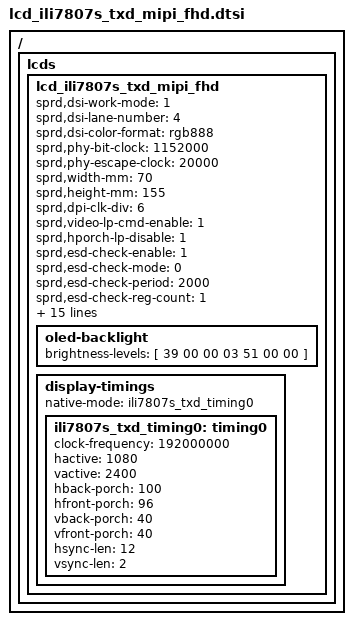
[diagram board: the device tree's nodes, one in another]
/*
 *  ili7807s LCD config dtsi file for spreadtrum
 *
 * Copyright (C) 2022, Spreadtrum Communications Inc.
 *
 * SPDX-License-Identifier: (GPL-2.0+ OR MIT)
 */
 
/ {
	fragment {
		target-path = "/";
		__overlay__ {
			lcds {
				lcd_ili7807s_txd_mipi_fhd: lcd_ili7807s_txd_mipi_fhd {

					sprd,dsi-work-mode = <1>;          /* video burst mode*/
					sprd,dsi-lane-number = <4>;
					sprd,dsi-color-format = "rgb888";

					sprd,phy-bit-clock = <1152000>;    /* kbps */
					sprd,phy-escape-clock = <20000>;   /* kHz */
					/* sprd,power-gpio-delay = <20>;      ms */
					sprd,width-mm = <70>;
					sprd,height-mm = <155>;
					sprd,dpi-clk-div = <6>;
					sprd,video-lp-cmd-enable = <1>;
					sprd,hporch-lp-disable = <1>;

					sprd,esd-check-enable = <1>;
					sprd,esd-check-mode = <0>;
					sprd,esd-check-period = <2000>;
					sprd,esd-check-reg-count = <1>;
					sprd,esd-check-register = [0A];
					sprd,esd-check-value-len = <1>;
					sprd,esd-check-value = [9C];
					sprd,reset-on-sequence = <1 5>, <0 5>, <1 20>;
					//sprd,reset-off-sequence = <0 5>;

					sprd,use-dcs-write;
					sprd,initial-command = [
						39 00 00 04 FF 78 07 06
						15 00 00 02 08 20
						15 00 00 02 3E E2
						15 00 00 02 4E 40
						15 00 00 02 4D 01
						15 00 00 02 48 09
						39 00 00 04 FF 78 07 03
						15 00 00 02 83 B8
						15 00 00 02 84 02
						15 00 00 02 8C D2
						15 00 00 02 8D D6
						15 00 00 02 8E DA
						15 00 00 02 8F DE
						15 00 00 02 90 DF
						15 00 00 02 91 E6
						15 00 00 02 92 E9
						15 00 00 02 93 ED
						15 00 00 02 94 F0
						15 00 00 02 95 FF
						15 00 00 02 96 B5
						15 00 00 02 97 BA
						15 00 00 02 98 BF
						15 00 00 02 99 C4
						15 00 00 02 9A C9
						15 00 00 02 9B CD
						15 00 00 02 9C D5
						15 00 00 02 9D E6
						15 00 00 02 9E F6
						15 00 00 02 9F FB
						15 00 00 02 87 4D
						39 00 00 04 FF 78 07 02
						15 00 00 02 1B 02
						39 00 00 04 FF 78 07 07
						15 00 00 02 29 80
						15 00 00 02 11 16
						15 00 00 02 29 00
						39 00 00 04 FF 78 07 00
						39 00 00 03 68 03 01
						39 00 00 03 51 00 00
						15 00 00 02 55 03
						15 00 00 02 53 2C
						15 00 00 02 35 00
						05 42 00 01 11
						05 10 00 01 29
					];
					sprd,sleep-in-command = [
						05 14 00 01 28
						05 58 00 01 10
					];
					sprd,sleep-out-command = [
						05 42 00 01 11
						05 10 00 01 29
					];
					sprd,cabc-on-command = [
						39 00 00 04 FF 78 07 00
						15 00 00 02 55 03
					];
					sprd,cabc-off-command = [
						39 00 00 04 FF 78 07 00
						15 00 00 02 55 00
					];
					oled-backlight{
						//default-brightness-level = <819>;
						//sprd,max-level = <2047>;
						brightness-levels = [
							39 00 00 03 51 00 00
						];
					};

					display-timings {
						native-mode = <&ili7807s_txd_timing0>;

						ili7807s_txd_timing0: timing0 {
							clock-frequency = <192000000>;
							hactive = <1080>;
							vactive = <2400>;
							hback-porch = <100>;
							hfront-porch = <96>;
							vback-porch = <40>;
							vfront-porch = <40>;
							hsync-len = <12>;
							vsync-len = <2>;

						};
					};
				};
			};
		};
	};
};

